# MSP430FR5969 register map
Vendor: msp430gen; File version: v0.4.0
Registers are 16-bit, read-write, reset 0x0 unless marked. A register's access mark holds for its fields unless they carry their own. Offsets are from the block's base; [hi:lo] are bit positions; {n}, {i} and the like mark numbered series.

## USCI_A0_UART_MODE
Base 0x000005C0
0x00 UCA0CTL1 8-bit — USCI A0 Control Register 1
0x01 UCA0CTL0 8-bit — USCI A0 Control Register 0
0x02 UCA0CTLW1 — USCI A0 Control Word Register 1
  [1:0] UCGLIT — USCI Deglitch Time Bit 1
    {v}=USCI Deglitch time: {v} (v=0..3)
0x06 UCA0BR0 8-bit — USCI A0 Baud Rate 0
0x07 UCA0BR1 8-bit — USCI A0 Baud Rate 1
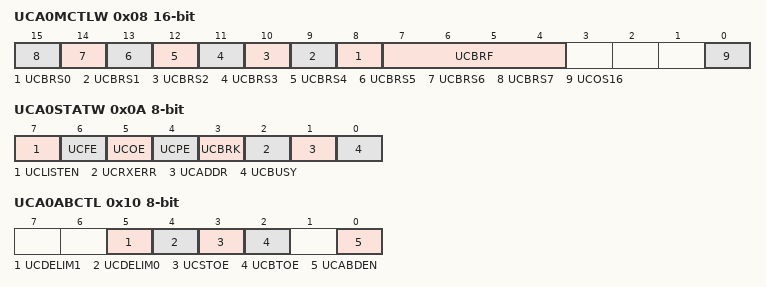
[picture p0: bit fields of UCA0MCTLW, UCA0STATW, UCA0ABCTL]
0x08 UCA0MCTLW — USCI A0 Modulation Control
  [n+8] UCBRS{n} (n=0..7) — USCI Second Stage Modulation Select {n}
  [7:4] UCBRF — USCI First Stage Modulation Select 3
    {v}=USCI First Stage Modulation: {v} (v=0..9); 10=USCI First Stage Modulation: A; 11=USCI First Stage Modulation: B; 12=USCI First Stage Modulation: C; 13=USCI First Stage Modulation: D; 14=USCI First Stage Modulation: E; 15=USCI First Stage Modulation: F
  [0] UCOS16 — USCI 16-times Oversampling enable
0x0A UCA0STATW 8-bit — USCI A0 Status Register
  [7] UCLISTEN — USCI Listen mode
  [6] UCFE — USCI Frame Error Flag
  [5] UCOE — USCI Overrun Error Flag
  [4] UCPE — USCI Parity Error Flag
  [3] UCBRK — USCI Break received
  [2] UCRXERR — USCI RX Error Flag
  [1] UCADDR — USCI Address received Flag
  [0] UCBUSY — USCI Busy Flag
0x0C UCA0RXBUF — USCI A0 Receive Buffer
0x0E UCA0TXBUF — USCI A0 Transmit Buffer
0x10 UCA0ABCTL 8-bit — USCI A0 LIN Control
  [5] UCDELIM1 — Break Sync Delimiter 1
  [4] UCDELIM0 — Break Sync Delimiter 0
  [3] UCSTOE — Sync-Field Timeout error
  [2] UCBTOE — Break Timeout error
  [0] UCABDEN — Auto Baud Rate detect enable
0x12 UCA0IRTCTL 8-bit — USCI A0 IrDA Transmit Control
0x13 UCA0IRRCTL 8-bit — USCI A0 IrDA Receive Control
0x1E UCA0IV — USCI A0 Interrupt Vector Register

## USCI_A0_SPI_MODE
Base 0x000005C0
0x00 UCA0CTL1_SPI 8-bit — USCI A0 Control Register 1
0x01 UCA0CTL0_SPI 8-bit — USCI A0 Control Register 0
0x06 UCA0BR0_SPI 8-bit — USCI A0 Baud Rate 0
0x07 UCA0BR1_SPI 8-bit — USCI A0 Baud Rate 1
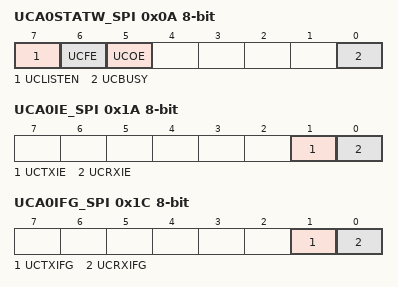
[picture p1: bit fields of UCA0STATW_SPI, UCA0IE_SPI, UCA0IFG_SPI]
0x0A UCA0STATW_SPI 8-bit — USCI A0 Status Register
  [7] UCLISTEN — USCI Listen mode
  [6] UCFE — USCI Frame Error Flag
  [5] UCOE — USCI Overrun Error Flag
  [0] UCBUSY — USCI Busy Flag
0x0C UCA0RXBUF_SPI — USCI A0 Receive Buffer
0x0E UCA0TXBUF_SPI — USCI A0 Transmit Buffer
0x1A UCA0IE_SPI 8-bit — USCI A0 Interrupt Enable Register
  [1] UCTXIE — USCI Transmit Interrupt Enable
  [0] UCRXIE — USCI Receive Interrupt Enable
0x1C UCA0IFG_SPI 8-bit — USCI A0 Interrupt Flags Register
  [1] UCTXIFG — SPI Transmit Interrupt Flag
  [0] UCRXIFG — SPI Receive Interrupt Flag
0x1E UCA0IV_SPI — USCI A0 Interrupt Vector Register

## USCI_A1_UART_MODE
Base 0x000005E0
0x00 UCA1CTL1 8-bit — USCI A1 Control Register 1
0x01 UCA1CTL0 8-bit — USCI A1 Control Register 0
0x02 UCA1CTLW1 — USCI A1 Control Word Register 1
  [1:0] UCGLIT — USCI Deglitch Time Bit 1
    {v}=USCI Deglitch time: {v} (v=0..3)
0x06 UCA1BR0 8-bit — USCI A1 Baud Rate 0
0x07 UCA1BR1 8-bit — USCI A1 Baud Rate 1
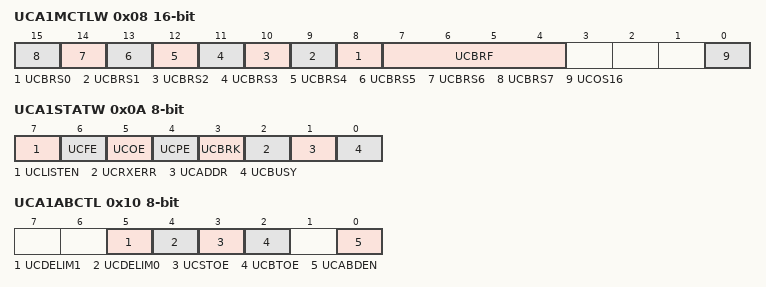
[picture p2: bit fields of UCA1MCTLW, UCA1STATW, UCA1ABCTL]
0x08 UCA1MCTLW — USCI A1 Modulation Control
  [n+8] UCBRS{n} (n=0..7) — USCI Second Stage Modulation Select {n}
  [7:4] UCBRF — USCI First Stage Modulation Select 3
    {v}=USCI First Stage Modulation: {v} (v=0..9); 10=USCI First Stage Modulation: A; 11=USCI First Stage Modulation: B; 12=USCI First Stage Modulation: C; 13=USCI First Stage Modulation: D; 14=USCI First Stage Modulation: E; 15=USCI First Stage Modulation: F
  [0] UCOS16 — USCI 16-times Oversampling enable
0x0A UCA1STATW 8-bit — USCI A1 Status Register
  [7] UCLISTEN — USCI Listen mode
  [6] UCFE — USCI Frame Error Flag
  [5] UCOE — USCI Overrun Error Flag
  [4] UCPE — USCI Parity Error Flag
  [3] UCBRK — USCI Break received
  [2] UCRXERR — USCI RX Error Flag
  [1] UCADDR — USCI Address received Flag
  [0] UCBUSY — USCI Busy Flag
0x0C UCA1RXBUF — USCI A1 Receive Buffer
0x0E UCA1TXBUF — USCI A1 Transmit Buffer
0x10 UCA1ABCTL 8-bit — USCI A1 LIN Control
  [5] UCDELIM1 — Break Sync Delimiter 1
  [4] UCDELIM0 — Break Sync Delimiter 0
  [3] UCSTOE — Sync-Field Timeout error
  [2] UCBTOE — Break Timeout error
  [0] UCABDEN — Auto Baud Rate detect enable
0x12 UCA1IRTCTL 8-bit — USCI A1 IrDA Transmit Control
0x13 UCA1IRRCTL 8-bit — USCI A1 IrDA Receive Control
0x1E UCA1IV — USCI A1 Interrupt Vector Register
